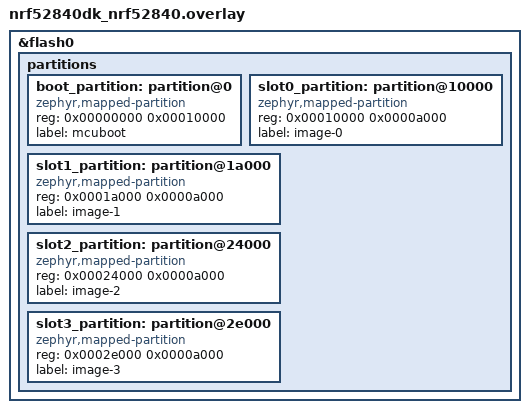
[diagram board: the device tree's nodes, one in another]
/*
 * Copyright (c) 2020 Nordic Semiconductor ASA
 *
 * SPDX-License-Identifier: Apache-2.0
 */

/delete-node/ &storage_partition;
/delete-node/ &slot0_partition;
/delete-node/ &slot1_partition;

&flash0 {
	partitions {
		ranges;
		#address-cells = <1>;
		#size-cells = <1>;

		boot_partition: partition@0 {
			compatible = "zephyr,mapped-partition";
			reg = <0x00000000 0x00010000>;
			label = "mcuboot";
		};

		slot0_partition: partition@10000 {
			compatible = "zephyr,mapped-partition";
			reg = <0x00010000 0x0000a000>;
			label = "image-0";
		};

		slot1_partition: partition@1a000 {
			compatible = "zephyr,mapped-partition";
			reg = <0x0001a000 0x0000a000>;
			label = "image-1";
		};

		slot2_partition: partition@24000 {
			compatible = "zephyr,mapped-partition";
			reg = <0x00024000 0x0000a000>;
			label = "image-2";
		};

		slot3_partition: partition@2e000 {
			compatible = "zephyr,mapped-partition";
			reg = <0x0002e000 0x0000a000>;
			label = "image-3";
		};
	};
};
